# GD32H77x_78x register map
File version: 1.0
CPU: CM7 r1p2, little endian, MPU, FPU, 4 interrupt priority bits
Registers are 32-bit, read-write, reset 0x0 unless marked. A register's access mark holds for its fields unless they carry their own. Offsets are from the block's base; [hi:lo] are bit positions.

## OSPI0 — Octal-SPI Interface 0
Base 0x52005000
Same registers: OSPI1 0x5200A000
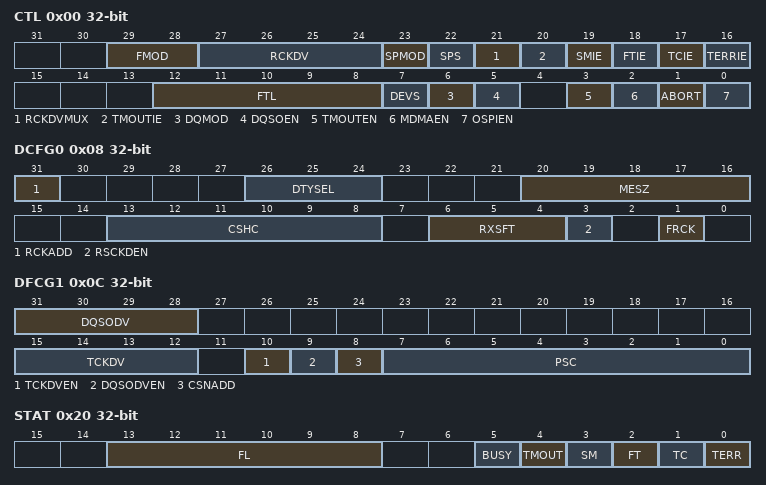
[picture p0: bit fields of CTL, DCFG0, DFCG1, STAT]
0x00 CTL — Control register
  [29:28] FMOD — Functional mode
  [27:24] RCKDV — Receive SCK delay value(RCKDVMUX must set 1)
  [23] SPMOD — Status polling match mode
  [22] SPS — Status polling mode stop
  [21] RCKDVMUX — Receive SCK delay chain select
  [20] TMOUTIE — Timeout interrupt enable
  [19] SMIE — Status match interrupt enable
  [18] FTIE — FIFO threshold interrupt enable
  [17] TCIE — Transfer complete interrupt enable
  [16] TERRIE — Transfer error interrupt enable
  [12:8] FTL — FIFO threshold level
  [7] DEVS — Device select
  [6] DQMOD — Dual-quad mode
  [5] DQSOEN — DQS output enable
  [3] TMOUTEN — Timeout counter enable
  [2] MDMAEN — MDMA enable
  [1] ABORT — Abort Request
  [0] OSPIEN — Enable OSPI
0x08 DCFG0 — Device configuration register 0
  [31] RCKADD — An additional clock is sent during reception, but the received data remains unchanged. To prevent DQS from missing an edge, configuration is required when choosing DQS for reception.
  [26:24] DTYSEL — Select device type
  [20:16] MESZ — Memory size
  [13:8] CSHC — Chip select high cycle
  [6:4] RXSFT — Shift receive step if receive data delay more than 1/2 cycle.
  [3] RSCKDEN — Sampling delay enable
  [1] FRCK — This bit indicates the SCK is free running or not when OSPI is free.
0x0C DFCG1 — Device configuration register 1
  [31:28] DQSODV — DQS out transfer SCK delay chain value
  [15:12] TCKDV — SCK transfer delay chain value
  [10] TCKDVEN — SCK transfer delay enable
  [9] DQSODVEN — DQS out transfer SCK delay enable
  [8] CSNADD — CSN add 1/2 cycle
  [7:0] PSC — This field defines the scaler factor for generating SCK based on the kernel clock (value+1)
0x14 DCFG3 — Device configuration register 3
  [31:0] REFRATE — Refresh rate
0x20 STAT ro — Status register
  [13:8] FL — FIFO level
  [5] BUSY
  [4] TMOUT — Timeout flag
  [3] SM — Status match flag
  [2] FT — FIFO threshold flag
  [1] TC — Transfer complete flag
  [0] TERR — This bit is set when an invalid address is being accessed in indirect mode. It is cleared by writing 1 to TERRC.
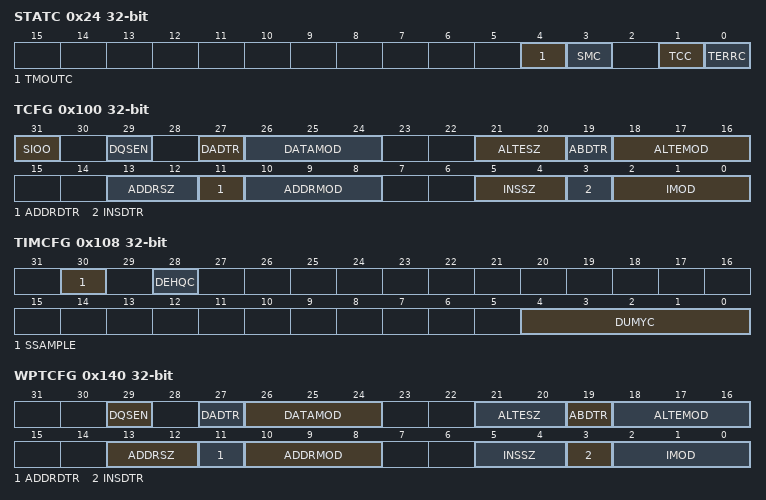
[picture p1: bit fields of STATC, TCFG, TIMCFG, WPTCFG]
0x24 STATC wo — Status clear register
  [4] TMOUTC — Clear timeout flag
  [3] SMC — Clear status match flag
  [1] TCC — Clear transfer complete flag
  [0] TERRC — Clear transfer error flag
0x40 DTLEN — Data length register
  [31:0] DTLEN — Data length
0x48 ADDR — Address register
  [31:0] ADDR — Address
0x50 DATA
0x80 STATMK — Status mask register
  [31:0] MASK — Status mask
0x88 STATMATCH — Status match register
  [31:0] MATCH — Status match
0x90 INTERVAL
  [15:0] INTERVAL — Interval cycle
0x100 TCFG — Transfer configuration register
  [31] SIOO — Send instruction only once mode
  [29] DQSEN — DQS enable
  [27] DADTR — Data double transfer rate
  [26:24] DATAMOD — Data mode
  [21:20] ALTESZ — Alternate bytes size
  [19] ABDTR — Alternate bytes double transfer rate
  [18:16] ALTEMOD — Alternate bytes mode
  [13:12] ADDRSZ — Address size
  [11] ADDRDTR — Address double transfer rate
  [10:8] ADDRMOD — Address mode
  [5:4] INSSZ — Instruction size
  [3] INSDTR — Instruction double transfer rate
  [2:0] IMOD — Instruction mode
0x108 TIMCFG — Timing configuration register
  [30] SSAMPLE — Sample shift
  [28] DEHQC — Delay hold 1/4 cycle
  [4:0] DUMYC — Number of dummy cycles
0x110 INS — Instruction register
  [31:0] INSTRUCTION
0x120 ALTE — Alternate bytes register
  [31:0] ALTE — Alternate bytes
0x130 LPOUT — Low power timeout register
  [15:0] TIMEOUT — Timeout cycle
0x140 WPTCFG — Wrap transfer configuration register
  [29] DQSEN — DQS enable
  [27] DADTR — Data double transfer rate
  [26:24] DATAMOD — Data mode
  [21:20] ALTESZ — Alternate bytes size
  [19] ABDTR — Alternate bytes double transfer rate
  [18:16] ALTEMOD — Alternate bytes mode
  [13:12] ADDRSZ — Address size
  [11] ADDRDTR — Address double transfer rate
  [10:8] ADDRMOD — Address mode
  [5:4] INSSZ — Instruction size
  [3] INSDTR — Instruction double transfer rate
  [2:0] IMOD — Instruction mode
0x148 WPTIMCFG — Wrap timing configuration register
  [4:0] DUMYC — Number of dummy cycles
0x150 WPINS — Wrap instruction register
  [31:0] INSTRUCTION
0x160 WPALTE — Wrap alternate byte register
  [31:0] ALTE — Alternate bytes
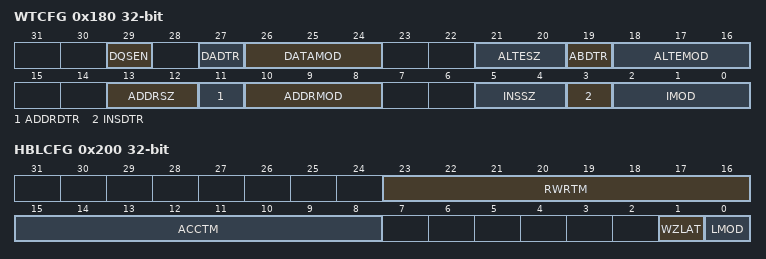
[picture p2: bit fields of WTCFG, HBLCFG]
0x180 WTCFG — Write transfer configuration register
  [29] DQSEN — DQS enable
  [27] DADTR — Data double transfer rate
  [26:24] DATAMOD — data mode
  [21:20] ALTESZ — Alternate bytes size
  [19] ABDTR — Alternate bytes double transfer rate
  [18:16] ALTEMOD — Alternate bytes mode
  [13:12] ADDRSZ — Address size
  [11] ADDRDTR — Address double transfer rate
  [10:8] ADDRMOD — Address mode
  [5:4] INSSZ — Instruction size
  [3] INSDTR — Instruction double transfer rate
  [2:0] IMOD — Instruction mode
0x188 WTIMCFG — Write timing configuration register
  [4:0] DUMYC — Number of dummy cycles
0x190 WINS — Write instruction register
  [31:0] INSTRUCTION
0x1A0 WALTE — Write alternate byte register
  [31:0] ALTE — Alternate bytes
0x200 HBLCFG — HyperBusTM latency configuration register
  [23:16] RWRTM — Read write recovery time
  [15:8] ACCTM — Access time
  [1] WZLAT — Write zero latency
  [0] LMOD — Latency mode
